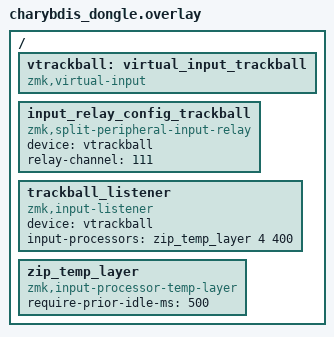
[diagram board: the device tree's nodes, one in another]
#include "charybdis-layouts.dtsi"
#include <dt-bindings/zmk/matrix_transform.h>

/ {
	vtrackball: virtual_input_trackball {
		compatible = "zmk,virtual-input";
	};

	input_relay_config_trackball {
		compatible = "zmk,split-peripheral-input-relay";
		device = <&vtrackball>;
		relay-channel = <111>;
	};

  trackball_listener {
      compatible = "zmk,input-listener";
      device = <&vtrackball>;
      input-processors = <&zip_temp_layer 4 400>;
  };

  /omit-if-no-ref/ zip_temp_layer: zip_temp_layer {
      compatible = "zmk,input-processor-temp-layer";
      #input-processor-cells = <2>;
      require-prior-idle-ms = <500>;
  };
};
